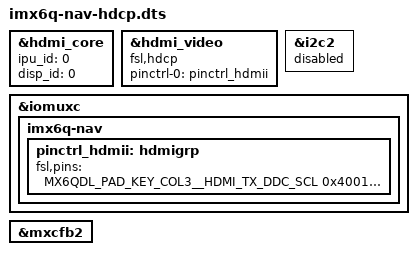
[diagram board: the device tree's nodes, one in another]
/*
 * Copyright 2015 Markus Niebel, TQ Systems GmbH
 *
 * The code contained herein is licensed under the GNU General Public
 * License. You may obtain a copy of the GNU General Public License
 * Version 2 or later at the following locations:
 *
 * http://www.opensource.org/licenses/gpl-license.html
 * http://www.gnu.org/copyleft/gpl.html
 */

#include "imx6q-nav-hdmi.dts"


&hdmi_core {
	ipu_id = <0>;
	disp_id = <0>;
	status = "okay";
};

&hdmi_video {
	fsl,hdcp;
	pinctrl-names = "default";
	pinctrl-0 = <&pinctrl_hdmii>;
	status = "okay";
};

&i2c2 {
	status = "disabled";
};

&iomuxc {
	imx6q-nav {
		pinctrl_hdmii: hdmigrp {
			fsl,pins = <
				MX6QDL_PAD_KEY_COL3__HDMI_TX_DDC_SCL 0x4001b899
				MX6QDL_PAD_KEY_ROW3__HDMI_TX_DDC_SDA 0x4001b899
			>;
		};
	};
};

&mxcfb2 {
	status = "okay";
};
